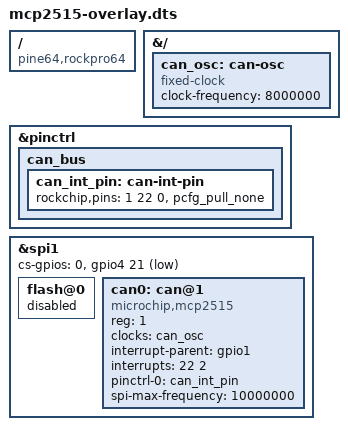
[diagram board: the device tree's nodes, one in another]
/dts-v1/;
/plugin/;

/ {
    compatible = "pine64,rockpro64", "rockchip,rk3399";
};

/* Define the external oscillator for the MCP2515 */
&{/} {
    can_osc: can-osc {
        compatible = "fixed-clock";
        #clock-cells = <0>;
        clock-frequency = <8000000>;
    };
};

&pinctrl {
    can_bus {
        can_int_pin: can-int-pin {
            rockchip,pins = <1 22 0 &pcfg_pull_none>;
        };
    };
};

&spi1 {
    status = "okay";
    #address-cells = <1>;
    #size-cells = <0>;
    cs-gpios = <0>, <&gpio4 21 1>;

    flash@0 {
        status = "disabled";
    };

    can0: can@1 {
        compatible = "microchip,mcp2515";
        reg = <1>;
        clocks = <&can_osc>;
        interrupt-parent = <&gpio1>;
        interrupts = <22 2>; /* PI-2 pin 11 / GPIO1_C6, IRQ_TYPE_EDGE_FALLING */

        pinctrl-names = "default";
        pinctrl-0 = <&can_int_pin>;

        spi-max-frequency = <10000000>;
        status = "okay";
    };
};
